# GD32W515Px register map
File version: 1.0
CPU: CM33 r0p0, little endian, MPU, FPU, 4 interrupt priority bits
Registers are 32-bit, read-write, reset 0x0 unless marked. A register's access mark holds for its fields unless they carry their own. Offsets are from the block's base; [hi:lo] are bit positions; {n}, {i} and the like mark numbered series.

## TZIAC — TrustZone illegal access controller
Base 0x400A0400
Same registers: SEC_TZIAC 0x500A0400
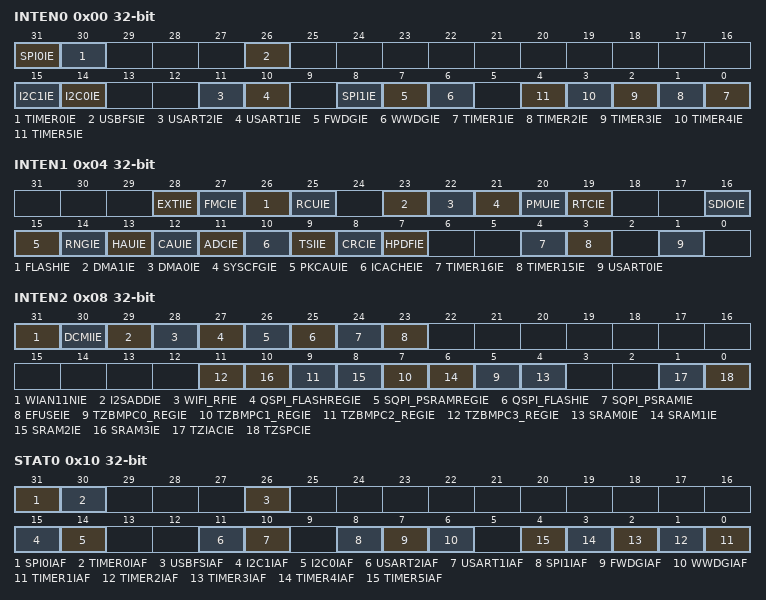
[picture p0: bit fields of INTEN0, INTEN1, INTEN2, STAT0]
0x00 INTEN0 — TZIAC interrupt enable register 0
  [31] SPI0IE — SPI0 illegal access interrupt enable bit
  [30] TIMER0IE — TIMER0 illegal access interrupt enable bit
  [26] USBFSIE — USBFS illegal access interrupt enable bit
  [15] I2C1IE — I2C1 illegal access interrupt enable bit
  [14] I2C0IE — I2C0 illegal access interrupt enable bit
  [11] USART2IE — USART2 illegal access interrupt enable bit
  [10] USART1IE — USART1 illegal access interrupt enable bit
  [8] SPI1IE — SPI1 illegal access interrupt enable bit
  [7] FWDGIE — FWDG illegal access interrupt enable bit
  [6] WWDGIE — WWDG illegal access interrupt enable bit
  [n-1] TIMER{n}IE (n=1..5) — TIMER{n} illegal access interrupt enable bit
0x04 INTEN1 — TZIAC interrupt enable register 1
  [28] EXTIIE — EXTI illegal access interrupt enable bit
  [27] FMCIE — FLASH REG illegal access interrupt enable bit
  [26] FLASHIE — FLASH illegal access interrupt enable bit
  [25] RCUIE — RCU illegal access interrupt enable bit
  [23] DMA1IE — DMA1 illegal access interrupt enable bit
  [22] DMA0IE — DMA0 illegal access interrupt enable bit
  [21] SYSCFGIE — SYSCFG illegal access interrupt enable bit
  [20] PMUIE — PWR illegal access interrupt enable bit
  [19] RTCIE — RTC illegal access interrupt enable bit
  [16] SDIOIE — SDIO illegal access interrupt enable bit
  [15] PKCAUIE — PKCAU illegal access interrupt enable bit
  [14] RNGIE — RNG illegal access interrupt enable bit
  [13] HAUIE — HAU illegal access interrupt enable bit
  [12] CAUIE — CAU illegal access interrupt enable bit
  [11] ADCIE — ADC illegal access interrupt enable bit
  [10] ICACHEIE — ICACHE_REG illegal access interrupt enable bit
  [9] TSIIE — TSI illegal access interrupt enable bit
  [8] CRCIE — CRC illegal access interrupt enable bit
  [7] HPDFIE — HPDF illegal access interrupt enable bit
  [4] TIMER16IE — TIMER16 illegal access interrupt enable bit
  [3] TIMER15IE — TIMER15 illegal access interrupt enable bit
  [1] USART0IE — USART0 illegal access interrupt enable bit
0x08 INTEN2 — TZIAC interrupt enable register 2
  [31] WIAN11NIE — WIAN11N illegal access interrupt enable bit
  [30] DCMIIE — DCMI illegal access interrupt enable bit
  [29] I2SADDIE — I2SADD illegal access interrupt enable bit
  [28] WIFI_RFIE — WIFI RF illegal access interrupt enable bit
  [27] QSPI_FLASHREGIE — QSPI FLASHREG illegal access interrupt enable bit
  [26] SQPI_PSRAMREGIE — SQPI PSRAMREG illegal access interrupt enable bit
  [25] QSPI_FLASHIE — QSPI FLASH illegal access interrupt enable bit
  [24] SQPI_PSRAMIE — SQPI PSRAM illegal access interrupt enable bit
  [23] EFUSEIE — EFUSE illegal access interrupt enable bit
  [2n+5] TZBMPC{n}_REGIE (n=0..3) — TZBMPC{n} REG illegal access interrupt enable bit
  [2n+4] SRAM{n}IE (n=0..3) — SRAM{n} illegal access interrupt enable bit
  [1] TZIACIE — TZIAC illegal access interrupt enable bit
  [0] TZSPCIE — TZSPC illegal access interrupt enable bit
0x10 STAT0 ro — TZIAC status register 0
  [31] SPI0IAF — SPI0 illegal access event flag bit
  [30] TIMER0IAF — TIMER0 illegal access event flag bit
  [26] USBFSIAF — USBFS illegal access event flag bit
  [15] I2C1IAF — I2C1 illegal access flag bit
  [14] I2C0IAF — I2C0 illegal access flag bit
  [11] USART2IAF — USART2 illegal access event flag bit
  [10] USART1IAF — USART1 illegal access event flag bit
  [8] SPI1IAF — SPI1 illegal access event flag bit
  [7] FWDGIAF — FWDG illegal access event flag bit
  [6] WWDGIAF — WWDG illegal access event flag bit
  [n-1] TIMER{n}IAF (n=1..5) — TIMER{n} illegal access event flag bit
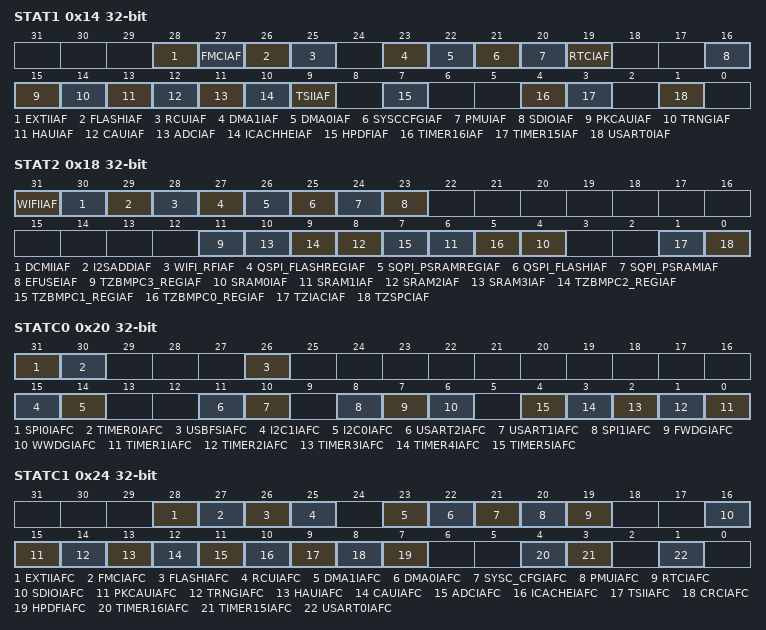
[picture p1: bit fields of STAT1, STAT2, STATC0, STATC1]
0x14 STAT1 ro — TZIAC status register 1
  [28] EXTIIAF — EXTI illegal access event flag bit
  [27] FMCIAF — FLASH illegal access event flag bit
  [26] FLASHIAF — FLASH illegal access event flag bit
  [25] RCUIAF — RCU illegal access event flag bit
  [23] DMA1IAF — DMA1 illegal access event flag bit
  [22] DMA0IAF — DMA0 illegal access event flag bit
  [21] SYSCCFGIAF — SYSCFG illegal access event flag bit
  [20] PMUIAF — PMU illegal access event flag bit
  [19] RTCIAF — RTC illegal access event flag bit
  [16] SDIOIAF — SDIO illegal access event flag bit
  [15] PKCAUIAF — PKCAU illegal access event flag bit
  [14] TRNGIAF — TRNG illegal access event flag bit
  [13] HAUIAF — HAU illegal access event flag bit
  [12] CAUIAF — CAU illegal access event flag bit
  [11] ADCIAF — ADC illegal access event flag bit
  [10] ICACHHEIAF — ICACHE illegal access event flag bit
  [9] TSIIAF — TSI illegal access event flag bit
  [7] HPDFIAF — HPDF illegal access event flag bit
  [4] TIMER16IAF — TIMER16 illegal access event flag bit
  [3] TIMER15IAF — TIMER15 illegal access event flag bit
  [1] USART0IAF — USART0 illegal access event flag bit
0x18 STAT2 — TZIAC status register 2
  [31] WIFIIAF — WIFI illegal access event flag bit
  [30] DCMIIAF — DCMI illegal access event flag bit
  [29] I2SADDIAF — I2SADD illegal access event flag bit
  [28] WIFI_RFIAF — EIFI RF illegal access event flag bit
  [27] QSPI_FLASHREGIAF — QSPI FLASHREG illegal access event flag bit
  [26] SQPI_PSRAMREGIAF — SQSPI PSRAMREG illegal access event flag bit
  [25] QSPI_FLASHIAF — QSPI FLASH illegal access event flag bit
  [24] SQPI_PSRAMIAF — SQPI PSRAM illegal access event flag bit
  [23] EFUSEIAF — EFUSE illegal access event flag bit
  [11] TZBMPC3_REGIAF — TZBMPC3 REG illegal access event flag bit
  [2n+4] SRAM{n}IAF (n=0..3) — SRAM{n} illegal access event flag bit
  [9] TZBMPC2_REGIAF — TZBMPC2 REG illegal access event flag bit
  [7] TZBMPC1_REGIAF — TZBMPC2 REG illegal access event flag bit
  [5] TZBMPC0_REGIAF — TZBMPC1 REG illegal access event flag bit
  [1] TZIACIAF — TZIAC illegal access event flag bit
  [0] TZSPCIAF — TZSPC illegal access event flag bit
0x20 STATC0 wo — TZIAC flag clear register 0
  [31] SPI0IAFC — SPI0 illegal access event flag clear bit
  [30] TIMER0IAFC — TIMER0 illegal access event flag clear bit
  [26] USBFSIAFC — USBFS illegal access event flag clear bit
  [15] I2C1IAFC — I2C1 illegal access flag clear bit
  [14] I2C0IAFC — I2C0 illegal access flag clear bit
  [11] USART2IAFC — USART2 illegal access event flag clear bit
  [10] USART1IAFC — USART1 illegal access event flag clear bit
  [8] SPI1IAFC — SPI1 illegal access event flag clear bit
  [7] FWDGIAFC — FWDG illegal access event flag clear bit
  [6] WWDGIAFC — WWDG illegal access event flag clear bit
  [n-1] TIMER{n}IAFC (n=1..5) — TIMER{n} illegal access event flag clear bit
0x24 STATC1 wo — TZIAC flag clear register 1
  [28] EXTIIAFC — EXTI illegal access event flag clear bit
  [27] FMCIAFC — FMC illegal access event flag clear bit
  [26] FLASHIAFC — FLASH illegal access event flag clear bit
  [25] RCUIAFC — RCU illegal access event flag clear bit
  [23] DMA1IAFC — DMA1 illegal access event flag clear bit
  [22] DMA0IAFC — DMA0 illegal access event flag clear bit
  [21] SYSC_CFGIAFC — SYS CFG illegal access event flag clear bit
  [20] PMUIAFC — PMU illegal access event flag clear bit
  [19] RTCIAFC — RTC illegal access event flag clear bit
  [16] SDIOIAFC — SDIO illegal access event flag clear bit
  [15] PKCAUIAFC — PKCAU illegal access event flag clear bit
  [14] TRNGIAFC — TRNG illegal access event flag clear bit
  [13] HAUIAFC — HAU illegal access event flag clear bit
  [12] CAUIAFC — CAU illegal access event flag clear bit
  [11] ADCIAFC — ADC illegal access event flag clear bit
  [10] ICACHEIAFC — ICACHE illegal access event flag clear bit
  [9] TSIIAFC — TSI illegal access event flag clear bit
  [8] CRCIAFC — CRC illegal access flag clear bit
  [7] HPDFIAFC — HPDF illegal access event flag clear bit
  [4] TIMER16IAFC — TIMER16 illegal access event flag clear bit
  [3] TIMER15IAFC — TIMER15 illegal access event flag clear bit
  [1] USART0IAFC — USART0 illegal access event flag clear bit
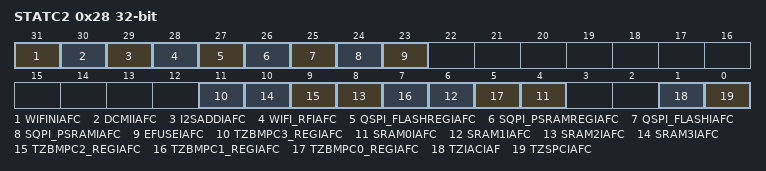
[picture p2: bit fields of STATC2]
0x28 STATC2 — TZIAC flag clear register 2
  [31] WIFINIAFC — WIFI illegal access event flag clear bit
  [30] DCMIIAFC — DCMI illegal access event flag clear bit
  [29] I2SADDIAFC — I2SADD illegal access event flag clear bit
  [28] WIFI_RFIAFC — EIFI RF illegal access event flag clear bit
  [27] QSPI_FLASHREGIAFC — QSPI FLASHREG illegal access event flag clear bit
  [26] SQPI_PSRAMREGIAFC — SQSPI PSRAMREG illegal access event flag clear bit
  [25] QSPI_FLASHIAFC — QSPI FLASH illegal access event flag clear bit
  [24] SQPI_PSRAMIAFC — SQPI PSRAM illegal access event flag clear bit
  [23] EFUSEIAFC — EFUSE illegal access event flag clear bit
  [11] TZBMPC3_REGIAFC — TZBMPC3 REG illegal access event flag clear bit
  [2n+4] SRAM{n}IAFC (n=0..3) — SRAM{n} illegal access event flag clear bit
  [9] TZBMPC2_REGIAFC — TZBMPC2 REG illegal access event flag clear bit
  [7] TZBMPC1_REGIAFC — TZBMPC2 REG illegal access event flag clear bit
  [5] TZBMPC0_REGIAFC — TZBMPC1 REG illegal access event flag clear bit
  [1] TZIACIAF — TZIAC illegal access event flag clear bit
  [0] TZSPCIAFC — TZSPC illegal access event flag clear bit
